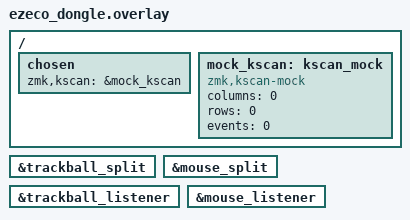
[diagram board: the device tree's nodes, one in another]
#include "ezeco.dtsi"

&trackball_split {
    status = "okay";
};

&mouse_split {
    status = "okay";
};

/ {
    chosen {
        zmk,kscan = &mock_kscan;
    };

    // The dongle has no keys of its own.
    mock_kscan: kscan_mock {
        compatible = "zmk,kscan-mock";
        columns = <0>;
        rows = <0>;
        events = <0>;
    };
};

&trackball_listener {
    status = "okay";
};

&mouse_listener {
    status = "okay";
};
